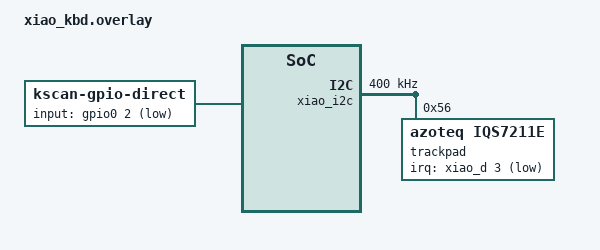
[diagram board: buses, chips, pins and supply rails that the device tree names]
#include <dt-bindings/zmk/matrix_transform.h>

/ {
    chosen {
        zmk,kscan = &kscan0;
        zmk,matrix_transform = &default_transform;
    };

    default_transform: keymap_transform_0 {
        compatible = "zmk,matrix-transform";
        columns = <1>;
        rows = <1>;
        map = <RC(0,0)>;
    };

    kscan0: kscan {
        compatible = "zmk,kscan-gpio-direct";
        label = "KSCAN";
        input-gpios = <&gpio0 2 (GPIO_ACTIVE_LOW | GPIO_PULL_UP)>;
    };

    trackpad_listener: trackpad_listener {
        compatible = "zmk,input-listener";
        device = <&trackpad>;
    };
};

&xiao_i2c {
    status = "okay";
    clock-frequency = <I2C_BITRATE_FAST>;
    zephyr,concat-buf-size = <32>;

    trackpad: trackpad@56 {
        compatible = "azoteq,iqs7211e";
        reg = <0x56>;
        status = "okay";
        irq-gpios = <&xiao_d 3 (GPIO_ACTIVE_LOW | GPIO_PULL_UP)>;
    };
};
